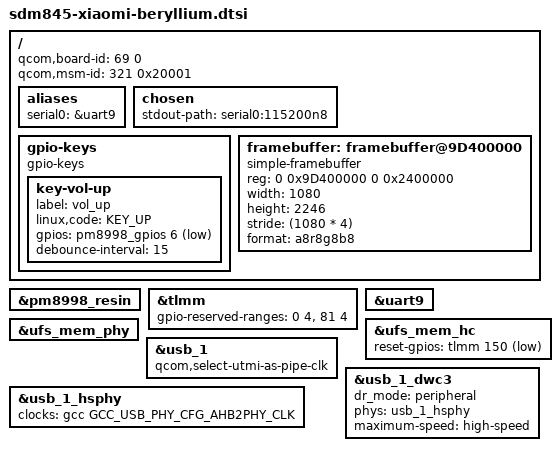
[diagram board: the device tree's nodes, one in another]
// SPDX-License-Identifier: GPL-2.0+
/*
 * OnePlus 6/6T (enchilada/fajita) board device tree source
 *
 * (C) Copyright 2023 Caleb Connolly <caleb.connolly@linaro.org>
 *
 */

/dts-v1/;

#include "sdm845.dtsi"
#include "pm8998.dtsi"

/ {
	/* required for bootloader to select correct board */
	qcom,board-id = <69 0>;
	qcom,msm-id = <321 0x20001>;

	aliases {
		serial0 = &uart9;
	};

	chosen {
		stdout-path = "serial0:115200n8";
	};

	gpio-keys {
		compatible = "gpio-keys";

		key-vol-up {
			label = "vol_up";
			linux,code = <KEY_UP>;
			gpios = <&pm8998_gpios 6 GPIO_ACTIVE_LOW>;
			debounce-interval = <15>;
		};
	};

	framebuffer: framebuffer@9D400000 {
		compatible = "simple-framebuffer";
		reg = <0 0x9D400000 0 0x2400000>;
		width = <1080>;
		height = <2246>;
		stride = <(1080 * 4)>;
		format = "a8r8g8b8";
	};
};

&pm8998_resin {
	status = "okay";
};

&tlmm {
	gpio-reserved-ranges = <0 4>, <81 4>;
};

&uart9 {
	status = "okay";
};

&ufs_mem_hc {
	status = "okay";

	reset-gpios = <&tlmm 150 GPIO_ACTIVE_LOW>;
};

&ufs_mem_phy {
	status = "okay";
};

&usb_1 {
	status = "okay";
	qcom,select-utmi-as-pipe-clk;
};

&usb_1_dwc3 {
	dr_mode = "peripheral";

	/* We don't support superspeed in u-boot so remove the SSPHY */
	phys = <&usb_1_hsphy>;
	phy-names = "usb2-phy";

	/* fastest mode for USB 2 */
	maximum-speed = "high-speed";
};

&usb_1_hsphy {
	/* Remove ref clk because rmphcc isn't available */
	clocks = <&gcc GCC_USB_PHY_CFG_AHB2PHY_CLK>;
	clock-names = "cfg_ahb";

	status = "okay";
};
